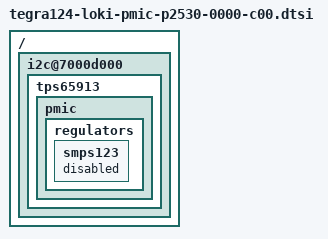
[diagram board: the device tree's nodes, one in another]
#include "tegra124-platforms/tegra124-loki-pmic-e2530-0000-a01.dtsi"

/ {
	i2c@7000d000 {
		tps65913 {
			pmic {
				regulators {
					smps123 {
						status="disabled";
					};
				};
			};
		};
	};
};
